# LM4F232H5QD register map
File version: 7944
Registers are 32-bit, read-write, no defined reset value unless marked. A register's access mark holds for its fields unless they carry their own. Offsets are from the block's base; [hi:lo] are bit positions; {n}, {i} and the like mark numbered series.

## SYSCTL — Register map for SYSCTL peripheral
Base 0x400FE000; register names take the prefix SYSCTL
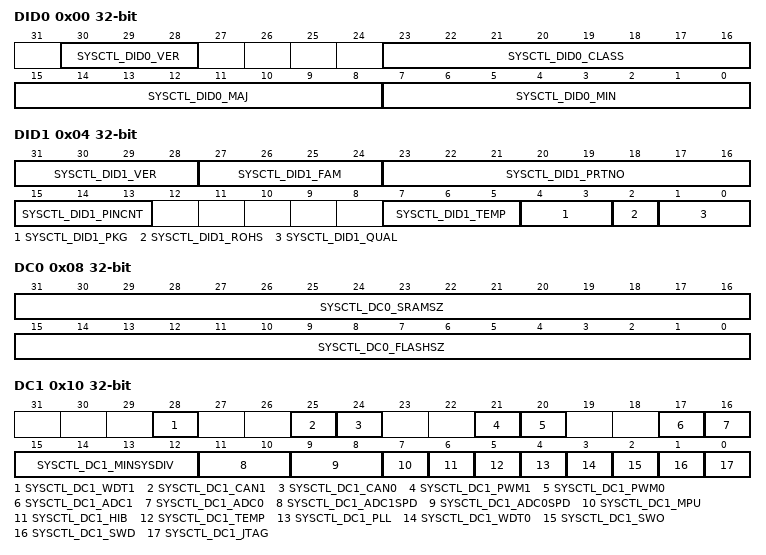
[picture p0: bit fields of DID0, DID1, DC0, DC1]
0x00 DID0 — Device Identification 0
  [30:28] SYSCTL_DID0_VER — DID0 Version
    1=Second version of the DID0 register format
  [23:16] SYSCTL_DID0_CLASS — Device Class
    5=SYSCTL_DID0_CLASS_BLIZZARD (Stellaris(R) Blizzard-class microcontrollers)
  [15:8] SYSCTL_DID0_MAJ — Major Revision
    0=SYSCTL_DID0_MAJ_REVA (Revision A (initial device)); 1=SYSCTL_DID0_MAJ_REVB (Revision B (first base layer revision)); 2=SYSCTL_DID0_MAJ_REVC (Revision C (second base layer revision))
  [7:0] SYSCTL_DID0_MIN — Minor Revision
    0=Initial device, or a major revision update; 1=First metal layer change; 2=Second metal layer change
0x04 DID1 — Device Identification 1
  [31:28] SYSCTL_DID1_VER — DID1 Version
    0=Initial DID1 register format definition, indicating a Stellaris LM3Snnn device; 1=Second version of the DID1 register format
  [27:24] SYSCTL_DID1_FAM — Family
    0=SYSCTL_DID1_FAM_STELLARIS (Stellaris family of microcontollers, that is, all devices with external part numbers starting with LM3S)
  [23:16] SYSCTL_DID1_PRTNO — Part Number
    197=SYSCTL_DID1_PRTNO_LM4F232H5QD (LM4F232H5QD)
  [15:13] SYSCTL_DID1_PINCNT — Package Pin Count
    0=28 pin package; 1=48-pin package; 2=100-pin package; 3=64-pin package; 4=144-pin package; 5=157-pin package
  [7:5] SYSCTL_DID1_TEMP — Temperature Range
    0=SYSCTL_DID1_TEMP_C (Commercial temperature range (0C to 70C)); 1=SYSCTL_DID1_TEMP_I (Industrial temperature range (-40C to 85C)); 2=SYSCTL_DID1_TEMP_E (Extended temperature range (-40C to 105C))
  [4:3] SYSCTL_DID1_PKG — Package Type
    0=SYSCTL_DID1_PKG_SOIC (SOIC package); 1=SYSCTL_DID1_PKG_QFP (LQFP package); 2=SYSCTL_DID1_PKG_BGA (BGA package)
  [2] SYSCTL_DID1_ROHS — RoHS-Compliance
  [1:0] SYSCTL_DID1_QUAL — Qualification Status
    0=SYSCTL_DID1_QUAL_ES (Engineering Sample (unqualified)); 1=SYSCTL_DID1_QUAL_PP (Pilot Production (unqualified)); 2=SYSCTL_DID1_QUAL_FQ (Fully Qualified)
0x08 DC0 — Device Capabilities 0
  [31:16] SYSCTL_DC0_SRAMSZ — SRAM Size
    7=SYSCTL_DC0_SRAMSZ_2KB (2 KB of SRAM); 15=SYSCTL_DC0_SRAMSZ_4KB (4 KB of SRAM); 23=SYSCTL_DC0_SRAMSZ_6KB (6 KB of SRAM); 31=SYSCTL_DC0_SRAMSZ_8KB (8 KB of SRAM); 47=SYSCTL_DC0_SRAMSZ_12KB (12 KB of SRAM); 63=SYSCTL_DC0_SRAMSZ_16KB (16 KB of SRAM); 79=SYSCTL_DC0_SRAMSZ_20KB (20 KB of SRAM); 95=SYSCTL_DC0_SRAMSZ_24KB (24 KB of SRAM); 127=SYSCTL_DC0_SRAMSZ_32KB (32 KB of SRAM)
  [15:0] SYSCTL_DC0_FLASHSZ — Flash Size
    3=SYSCTL_DC0_FLASHSZ_8KB (8 KB of Flash); 7=SYSCTL_DC0_FLASHSZ_16KB (16 KB of Flash); 15=SYSCTL_DC0_FLASHSZ_32KB (32 KB of Flash); 31=SYSCTL_DC0_FLASHSZ_64KB (64 KB of Flash); 47=SYSCTL_DC0_FLASHSZ_96KB (96 KB of Flash); 63=SYSCTL_DC0_FLASHSZ_128K (128 KB of Flash); 95=SYSCTL_DC0_FLASHSZ_192K (192 KB of Flash); 127=SYSCTL_DC0_FLASHSZ_256K (256 KB of Flash)
0x10 DC1 — Device Capabilities 1
  [28] SYSCTL_DC1_WDT1 — Watchdog Timer1 Present
  [25] SYSCTL_DC1_CAN1 — CAN Module 1 Present
  [24] SYSCTL_DC1_CAN0 — CAN Module 0 Present
  [21] SYSCTL_DC1_PWM1 — PWM Module 1 Present
  [20] SYSCTL_DC1_PWM0 — PWM Module 0 Present
  [17] SYSCTL_DC1_ADC1 — ADC Module 1 Present
  [16] SYSCTL_DC1_ADC0 — ADC Module 0 Present
  [15:12] SYSCTL_DC1_MINSYSDIV — System Clock Divider
    1=Divide VCO (400MHZ) by 5 minimum; 2=Divide VCO (400MHZ) by 2*2 + 2 = 6 minimum; 3=Specifies a 50-MHz CPU clock with a PLL divider of 4; 4=Specifies a 40-MHz CPU clock with a PLL divider of 5; 7=Specifies a 25-MHz clock with a PLL divider of 8; 9=Specifies a 20-MHz clock with a PLL divider of 10
  [11:10] SYSCTL_DC1_ADC1SPD — Max ADC1 Speed
    0=SYSCTL_DC1_ADC1SPD_125K (125K samples/second); 1=SYSCTL_DC1_ADC1SPD_250K (250K samples/second); 2=SYSCTL_DC1_ADC1SPD_500K (500K samples/second); 3=SYSCTL_DC1_ADC1SPD_1M (1M samples/second)
  [9:8] SYSCTL_DC1_ADC0SPD — Max ADC0 Speed
    0=SYSCTL_DC1_ADC0SPD_125K (125K samples/second); 1=SYSCTL_DC1_ADC0SPD_250K (250K samples/second); 2=SYSCTL_DC1_ADC0SPD_500K (500K samples/second); 3=SYSCTL_DC1_ADC0SPD_1M (1M samples/second)
  [7] SYSCTL_DC1_MPU — MPU Present
  [6] SYSCTL_DC1_HIB — Hibernation Module Present
  [5] SYSCTL_DC1_TEMP — Temp Sensor Present
  [4] SYSCTL_DC1_PLL — PLL Present
  [3] SYSCTL_DC1_WDT0 — Watchdog Timer 0 Present
  [2] SYSCTL_DC1_SWO — SWO Trace Port Present
  [1] SYSCTL_DC1_SWD — SWD Present
  [0] SYSCTL_DC1_JTAG — JTAG Present
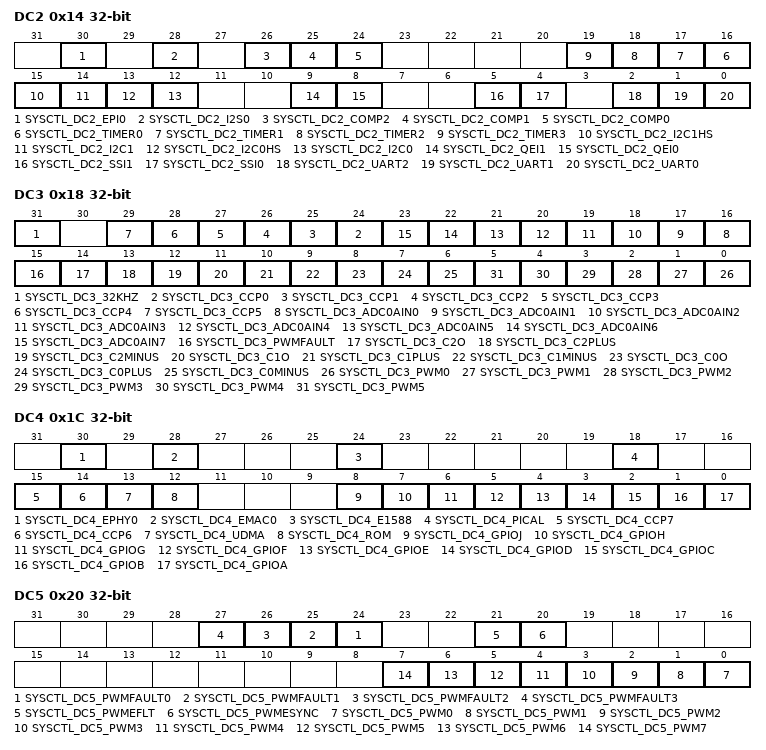
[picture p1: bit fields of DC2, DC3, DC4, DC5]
0x14 DC2 — Device Capabilities 2
  [30] SYSCTL_DC2_EPI0 — EPI Module 0 Present
  [28] SYSCTL_DC2_I2S0 — I2S Module 0 Present
  [26] SYSCTL_DC2_COMP2 — Analog Comparator 2 Present
  [25] SYSCTL_DC2_COMP1 — Analog Comparator 1 Present
  [24] SYSCTL_DC2_COMP0 — Analog Comparator 0 Present
  [n+16] SYSCTL_DC2_TIMER{n} (n=0..3) — Timer Module {n} Present
  [15] SYSCTL_DC2_I2C1HS — I2C Module 1 Speed
  [14] SYSCTL_DC2_I2C1 — I2C Module 1 Present
  [13] SYSCTL_DC2_I2C0HS — I2C Module 0 Speed
  [12] SYSCTL_DC2_I2C0 — I2C Module 0 Present
  [9] SYSCTL_DC2_QEI1 — QEI Module 1 Present
  [8] SYSCTL_DC2_QEI0 — QEI Module 0 Present
  [5] SYSCTL_DC2_SSI1 — SSI Module 1 Present
  [4] SYSCTL_DC2_SSI0 — SSI Module 0 Present
  [2] SYSCTL_DC2_UART2 — UART Module 2 Present
  [1] SYSCTL_DC2_UART1 — UART Module 1 Present
  [0] SYSCTL_DC2_UART0 — UART Module 0 Present
0x18 DC3 — Device Capabilities 3
  [31] SYSCTL_DC3_32KHZ — 32KHz Input Clock Available
  [n+24] SYSCTL_DC3_CCP{n} (n=0..5) — CCP{n} Pin Present
  [n+16] SYSCTL_DC3_ADC0AIN{n} (n=0..7) — ADC Module 0 AIN{n} Pin Present
  [15] SYSCTL_DC3_PWMFAULT — PWM Fault Pin Present
  [14] SYSCTL_DC3_C2O — C2o Pin Present
  [13] SYSCTL_DC3_C2PLUS — C2+ Pin Present
  [12] SYSCTL_DC3_C2MINUS — C2- Pin Present
  [11] SYSCTL_DC3_C1O — C1o Pin Present
  [10] SYSCTL_DC3_C1PLUS — C1+ Pin Present
  [9] SYSCTL_DC3_C1MINUS — C1- Pin Present
  [8] SYSCTL_DC3_C0O — C0o Pin Present
  [7] SYSCTL_DC3_C0PLUS — C0+ Pin Present
  [6] SYSCTL_DC3_C0MINUS — C0- Pin Present
  [n] SYSCTL_DC3_PWM{n} (n=0..5) — PWM{n} Pin Present
0x1C DC4 — Device Capabilities 4
  [30] SYSCTL_DC4_EPHY0 — Ethernet PHY Layer 0 Present
  [28] SYSCTL_DC4_EMAC0 — Ethernet MAC Layer 0 Present
  [24] SYSCTL_DC4_E1588 — 1588 Capable
  [18] SYSCTL_DC4_PICAL — PIOSC Calibrate
  [15] SYSCTL_DC4_CCP7 — CCP7 Pin Present
  [14] SYSCTL_DC4_CCP6 — CCP6 Pin Present
  [13] SYSCTL_DC4_UDMA — Micro-DMA Module Present
  [12] SYSCTL_DC4_ROM — Internal Code ROM Present
  [8] SYSCTL_DC4_GPIOJ — GPIO Port J Present
  [7] SYSCTL_DC4_GPIOH — GPIO Port H Present
  [6] SYSCTL_DC4_GPIOG — GPIO Port G Present
  [5] SYSCTL_DC4_GPIOF — GPIO Port F Present
  [4] SYSCTL_DC4_GPIOE — GPIO Port E Present
  [3] SYSCTL_DC4_GPIOD — GPIO Port D Present
  [2] SYSCTL_DC4_GPIOC — GPIO Port C Present
  [1] SYSCTL_DC4_GPIOB — GPIO Port B Present
  [0] SYSCTL_DC4_GPIOA — GPIO Port A Present
0x20 DC5 — Device Capabilities 5
  [n+24] SYSCTL_DC5_PWMFAULT{n} (n=0..3) — PWM Fault {n} Pin Present
  [21] SYSCTL_DC5_PWMEFLT — PWM Extended Fault Active
  [20] SYSCTL_DC5_PWMESYNC — PWM Extended SYNC Active
  [n] SYSCTL_DC5_PWM{n} (n=0..7) — PWM{n} Pin Present
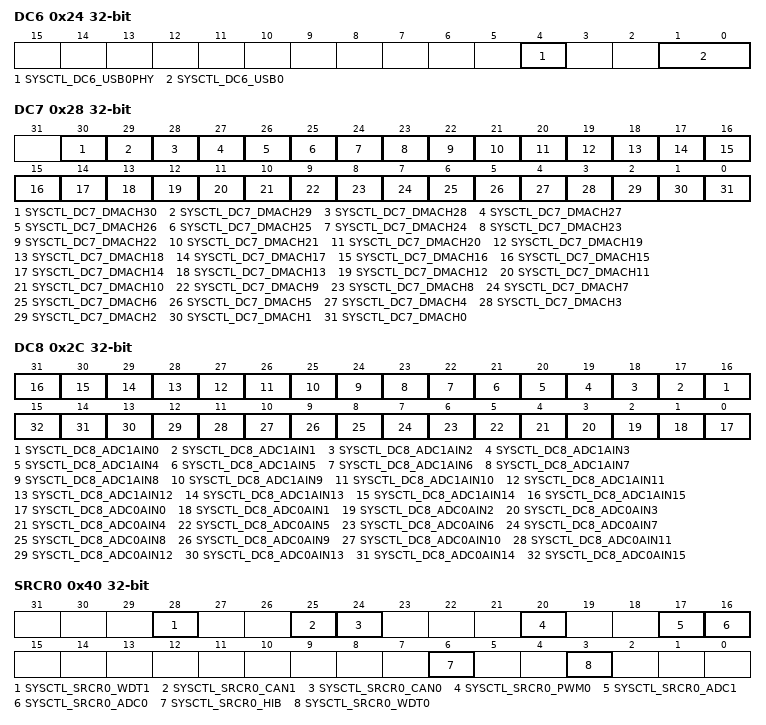
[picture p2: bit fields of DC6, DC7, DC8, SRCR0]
0x24 DC6 — Device Capabilities 6
  [4] SYSCTL_DC6_USB0PHY — USB Module 0 PHY Present
  [1:0] SYSCTL_DC6_USB0 — USB Module 0 Present
    1=SYSCTL_DC6_USB0_DEV (USB0 is Device Only); 2=SYSCTL_DC6_USB0_HOSTDEV (USB is Device or Host); 3=SYSCTL_DC6_USB0_OTG (USB0 is OTG)
0x28 DC7 — Device Capabilities 7
  [30] SYSCTL_DC7_DMACH30 — SW
  [29] SYSCTL_DC7_DMACH29 — I2S0_TX / CAN1_TX
  [28] SYSCTL_DC7_DMACH28 — I2S0_RX / CAN1_RX
  [27] SYSCTL_DC7_DMACH27 — CAN1_TX / ADC1_SS3
  [26] SYSCTL_DC7_DMACH26 — CAN1_RX / ADC1_SS2
  [25] SYSCTL_DC7_DMACH25 — SSI1_TX / ADC1_SS1
  [24] SYSCTL_DC7_DMACH24 — SSI1_RX / ADC1_SS0
  [23] SYSCTL_DC7_DMACH23 — UART1_TX / CAN2_TX
  [22] SYSCTL_DC7_DMACH22 — UART1_RX / CAN2_RX
  [21] SYSCTL_DC7_DMACH21 — Timer1B / EPI0_WFIFO
  [20] SYSCTL_DC7_DMACH20 — Timer1A / EPI0_NBRFIFO
  [19] SYSCTL_DC7_DMACH19 — Timer0B / Timer1B
  [18] SYSCTL_DC7_DMACH18 — Timer0A / Timer1A
  [17] SYSCTL_DC7_DMACH17 — ADC0_SS3
  [16] SYSCTL_DC7_DMACH16 — ADC0_SS2
  [15] SYSCTL_DC7_DMACH15 — ADC0_SS1 / Timer2B
  [14] SYSCTL_DC7_DMACH14 — ADC0_SS0 / Timer2A
  [13] SYSCTL_DC7_DMACH13 — CAN0_TX / UART2_TX
  [12] SYSCTL_DC7_DMACH12 — CAN0_RX / UART2_RX
  [11] SYSCTL_DC7_DMACH11 — SSI0_TX / SSI1_TX
  [10] SYSCTL_DC7_DMACH10 — SSI0_RX / SSI1_RX
  [9] SYSCTL_DC7_DMACH9 — UART0_TX / UART1_TX
  [8] SYSCTL_DC7_DMACH8 — UART0_RX / UART1_RX
  [7] SYSCTL_DC7_DMACH7 — ETH_TX / Timer2B
  [6] SYSCTL_DC7_DMACH6 — ETH_RX / Timer2A
  [5] SYSCTL_DC7_DMACH5 — USB_EP3_TX / Timer2B
  [4] SYSCTL_DC7_DMACH4 — USB_EP3_RX / Timer2A
  [3] SYSCTL_DC7_DMACH3 — USB_EP2_TX / Timer3B
  [2] SYSCTL_DC7_DMACH2 — USB_EP2_RX / Timer3A
  [1] SYSCTL_DC7_DMACH1 — USB_EP1_TX / UART2_TX
  [0] SYSCTL_DC7_DMACH0 — USB_EP1_RX / UART2_RX
0x2C DC8 — Device Capabilities 8 ADC Channels
  [n+16] SYSCTL_DC8_ADC1AIN{n} (n=0..15) — ADC Module 1 AIN{n} Pin Present
  [n] SYSCTL_DC8_ADC0AIN{n} (n=0..15) — ADC Module 0 AIN{n} Pin Present
0x30 PBORCTL — Brown-Out Reset Control
  [1] SYSCTL_PBORCTL_BORIOR — BOR Interrupt or Reset
0x40 SRCR0 — Software Reset Control 0
  [28] SYSCTL_SRCR0_WDT1 — WDT1 Reset Control
  [25] SYSCTL_SRCR0_CAN1 — CAN1 Reset Control
  [24] SYSCTL_SRCR0_CAN0 — CAN0 Reset Control
  [20] SYSCTL_SRCR0_PWM0 — PWM Reset Control
  [17] SYSCTL_SRCR0_ADC1 — ADC1 Reset Control
  [16] SYSCTL_SRCR0_ADC0 — ADC0 Reset Control
  [6] SYSCTL_SRCR0_HIB — HIB Reset Control
  [3] SYSCTL_SRCR0_WDT0 — WDT0 Reset Control
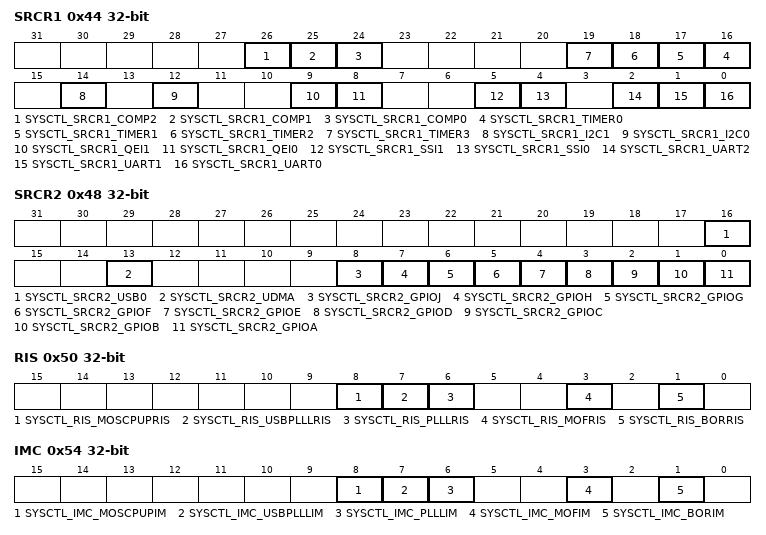
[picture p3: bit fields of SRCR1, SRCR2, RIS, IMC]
0x44 SRCR1 — Software Reset Control 1
  [26] SYSCTL_SRCR1_COMP2 — Analog Comp 2 Reset Control
  [25] SYSCTL_SRCR1_COMP1 — Analog Comp 1 Reset Control
  [24] SYSCTL_SRCR1_COMP0 — Analog Comp 0 Reset Control
  [n+16] SYSCTL_SRCR1_TIMER{n} (n=0..3) — Timer {n} Reset Control
  [14] SYSCTL_SRCR1_I2C1 — I2C1 Reset Control
  [12] SYSCTL_SRCR1_I2C0 — I2C0 Reset Control
  [9] SYSCTL_SRCR1_QEI1 — QEI1 Reset Control
  [8] SYSCTL_SRCR1_QEI0 — QEI0 Reset Control
  [5] SYSCTL_SRCR1_SSI1 — SSI1 Reset Control
  [4] SYSCTL_SRCR1_SSI0 — SSI0 Reset Control
  [2] SYSCTL_SRCR1_UART2 — UART2 Reset Control
  [1] SYSCTL_SRCR1_UART1 — UART1 Reset Control
  [0] SYSCTL_SRCR1_UART0 — UART0 Reset Control
0x48 SRCR2 — Software Reset Control 2
  [16] SYSCTL_SRCR2_USB0 — USB0 Reset Control
  [13] SYSCTL_SRCR2_UDMA — Micro-DMA Reset Control
  [8] SYSCTL_SRCR2_GPIOJ — Port J Reset Control
  [7] SYSCTL_SRCR2_GPIOH — Port H Reset Control
  [6] SYSCTL_SRCR2_GPIOG — Port G Reset Control
  [5] SYSCTL_SRCR2_GPIOF — Port F Reset Control
  [4] SYSCTL_SRCR2_GPIOE — Port E Reset Control
  [3] SYSCTL_SRCR2_GPIOD — Port D Reset Control
  [2] SYSCTL_SRCR2_GPIOC — Port C Reset Control
  [1] SYSCTL_SRCR2_GPIOB — Port B Reset Control
  [0] SYSCTL_SRCR2_GPIOA — Port A Reset Control
0x50 RIS — Raw Interrupt Status
  [8] SYSCTL_RIS_MOSCPUPRIS — MOSC Power Up Raw Interrupt Status
  [7] SYSCTL_RIS_USBPLLLRIS — USB PLL Lock Raw Interrupt Status
  [6] SYSCTL_RIS_PLLLRIS — PLL Lock Raw Interrupt Status
  [3] SYSCTL_RIS_MOFRIS — Main Oscillator Fault Raw Interrupt Status
  [1] SYSCTL_RIS_BORRIS — Brown-Out Reset Raw Interrupt Status
0x54 IMC — Interrupt Mask Control
  [8] SYSCTL_IMC_MOSCPUPIM — MOSC Power Up Interrupt Mask
  [7] SYSCTL_IMC_USBPLLLIM — USB PLL Lock Interrupt Mask
  [6] SYSCTL_IMC_PLLLIM — PLL Lock Interrupt Mask
  [3] SYSCTL_IMC_MOFIM — Main Oscillator Fault Interrupt Mask
  [1] SYSCTL_IMC_BORIM — Brown-Out Reset Interrupt Mask
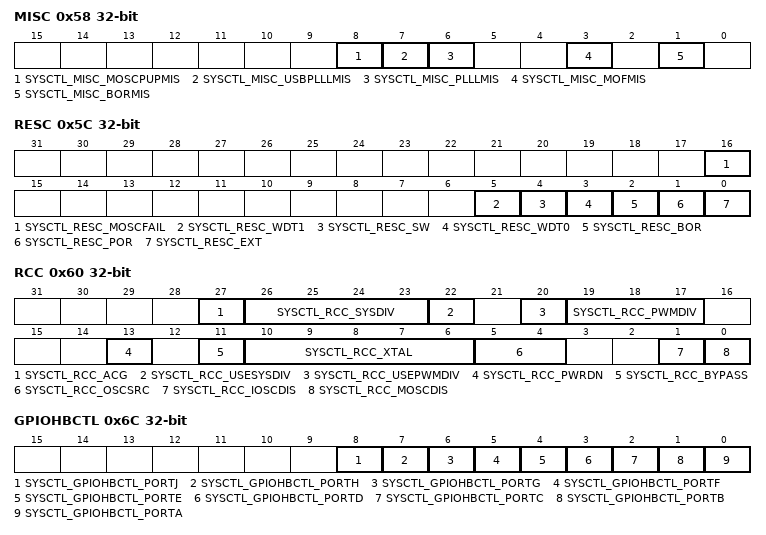
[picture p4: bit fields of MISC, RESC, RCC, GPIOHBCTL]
0x58 MISC — Masked Interrupt Status and Clear
  [8] SYSCTL_MISC_MOSCPUPMIS — MOSC Power Up Masked Interrupt Status
  [7] SYSCTL_MISC_USBPLLLMIS — USB PLL Lock Masked Interrupt Status
  [6] SYSCTL_MISC_PLLLMIS — PLL Lock Masked Interrupt Status
  [3] SYSCTL_MISC_MOFMIS — Main Oscillator Fault Masked Interrupt Status
  [1] SYSCTL_MISC_BORMIS — BOR Masked Interrupt Status
0x5C RESC — Reset Cause
  [16] SYSCTL_RESC_MOSCFAIL — MOSC Failure Reset
  [5] SYSCTL_RESC_WDT1 — Watchdog Timer 1 Reset
  [4] SYSCTL_RESC_SW — Software Reset
  [3] SYSCTL_RESC_WDT0 — Watchdog Timer 0 Reset
  [2] SYSCTL_RESC_BOR — Brown-Out Reset
  [1] SYSCTL_RESC_POR — Power-On Reset
  [0] SYSCTL_RESC_EXT — External Reset
0x60 RCC — Run-Mode Clock Configuration
  [27] SYSCTL_RCC_ACG — Auto Clock Gating
  [26:23] SYSCTL_RCC_SYSDIV — System Clock Divisor
  [22] SYSCTL_RCC_USESYSDIV — Enable System Clock Divider
  [20] SYSCTL_RCC_USEPWMDIV — Enable PWM Clock Divisor
  [19:17] SYSCTL_RCC_PWMDIV — PWM Unit Clock Divisor
    0=PWM clock /2; 1=PWM clock /4; 2=PWM clock /8; 3=PWM clock /16; 4=PWM clock /32; 5=PWM clock /64
  [13] SYSCTL_RCC_PWRDN — PLL Power Down
  [11] SYSCTL_RCC_BYPASS — PLL Bypass
  [10:6] SYSCTL_RCC_XTAL — Crystal Value
    6=SYSCTL_RCC_XTAL_4MHZ (4 MHz); 7=SYSCTL_RCC_XTAL_4_09MHZ (4.096 MHz); 8=SYSCTL_RCC_XTAL_4_91MHZ (4.9152 MHz); 9=SYSCTL_RCC_XTAL_5MHZ (5 MHz); 10=SYSCTL_RCC_XTAL_5_12MHZ (5.12 MHz); 11=SYSCTL_RCC_XTAL_6MHZ (6 MHz); 12=SYSCTL_RCC_XTAL_6_14MHZ (6.144 MHz); 13=SYSCTL_RCC_XTAL_7_37MHZ (7.3728 MHz); 14=SYSCTL_RCC_XTAL_8MHZ (8 MHz); 15=SYSCTL_RCC_XTAL_8_19MHZ (8.192 MHz); 16=SYSCTL_RCC_XTAL_10MHZ (10 MHz); 17=SYSCTL_RCC_XTAL_12MHZ (12 MHz); 18=SYSCTL_RCC_XTAL_12_2MHZ (12.288 MHz); 19=SYSCTL_RCC_XTAL_13_5MHZ (13.56 MHz); 20=SYSCTL_RCC_XTAL_14_3MHZ (14.31818 MHz); 21=SYSCTL_RCC_XTAL_16MHZ (16 MHz); 22=SYSCTL_RCC_XTAL_16_3MHZ (16.384 MHz); 23=SYSCTL_RCC_XTAL_18MHZ (18.0 MHz); 24=SYSCTL_RCC_XTAL_20MHZ (20.0 MHz); 25=SYSCTL_RCC_XTAL_24MHZ (24.0 MHz); 26=SYSCTL_RCC_XTAL_25MHZ (25.0 MHz)
  [5:4] SYSCTL_RCC_OSCSRC — Oscillator Source
    0=SYSCTL_RCC_OSCSRC_MAIN (MOSC); 1=SYSCTL_RCC_OSCSRC_INT (IOSC); 2=SYSCTL_RCC_OSCSRC_INT4 (IOSC/4); 3=30 kHz
  [1] SYSCTL_RCC_IOSCDIS — Internal Oscillator Disable
  [0] SYSCTL_RCC_MOSCDIS — Main Oscillator Disable
0x6C GPIOHBCTL — GPIO High-Performance Bus Control
  [8] SYSCTL_GPIOHBCTL_PORTJ — Port J Advanced High-Performance Bus
  [7] SYSCTL_GPIOHBCTL_PORTH — Port H Advanced High-Performance Bus
  [6] SYSCTL_GPIOHBCTL_PORTG — Port G Advanced High-Performance Bus
  [5] SYSCTL_GPIOHBCTL_PORTF — Port F Advanced High-Performance Bus
  [4] SYSCTL_GPIOHBCTL_PORTE — Port E Advanced High-Performance Bus
  [3] SYSCTL_GPIOHBCTL_PORTD — Port D Advanced High-Performance Bus
  [2] SYSCTL_GPIOHBCTL_PORTC — Port C Advanced High-Performance Bus
  [1] SYSCTL_GPIOHBCTL_PORTB — Port B Advanced High-Performance Bus
  [0] SYSCTL_GPIOHBCTL_PORTA — Port A Advanced High-Performance Bus
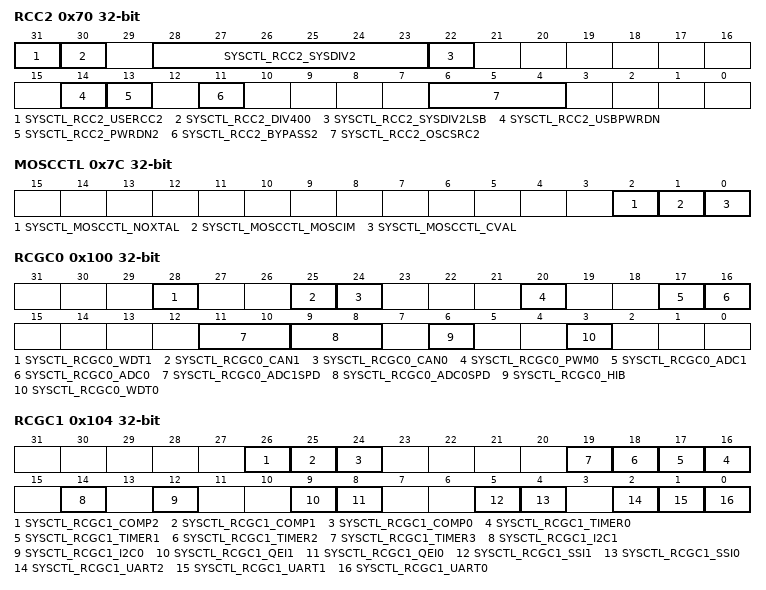
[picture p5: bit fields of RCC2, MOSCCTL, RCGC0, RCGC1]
0x70 RCC2 — Run-Mode Clock Configuration 2
  [31] SYSCTL_RCC2_USERCC2 — Use RCC2
  [30] SYSCTL_RCC2_DIV400 — Divide PLL as 400 MHz vs. 200 MHz
  [28:23] SYSCTL_RCC2_SYSDIV2 — System Clock Divisor 2
    {v}=System clock /{v+1} (v=1..63)
  [22] SYSCTL_RCC2_SYSDIV2LSB — Additional LSB for SYSDIV2
  [14] SYSCTL_RCC2_USBPWRDN — Power-Down USB PLL
  [13] SYSCTL_RCC2_PWRDN2 — Power-Down PLL 2
  [11] SYSCTL_RCC2_BYPASS2 — PLL Bypass 2
  [6:4] SYSCTL_RCC2_OSCSRC2 — Oscillator Source 2
    0=SYSCTL_RCC2_OSCSRC2_MO (MOSC); 1=SYSCTL_RCC2_OSCSRC2_IO (PIOSC); 2=SYSCTL_RCC2_OSCSRC2_IO4 (PIOSC/4); 3=30 kHz; 7=32.768 kHz
0x7C MOSCCTL — Main Oscillator Control
  [2] SYSCTL_MOSCCTL_NOXTAL — No Crystal Connected
  [1] SYSCTL_MOSCCTL_MOSCIM — MOSC Failure Action
  [0] SYSCTL_MOSCCTL_CVAL — Clock Validation for MOSC
0x100 RCGC0 — Run Mode Clock Gating Control Register 0
  [28] SYSCTL_RCGC0_WDT1 — WDT1 Clock Gating Control
  [25] SYSCTL_RCGC0_CAN1 — CAN1 Clock Gating Control
  [24] SYSCTL_RCGC0_CAN0 — CAN0 Clock Gating Control
  [20] SYSCTL_RCGC0_PWM0 — PWM Clock Gating Control
  [17] SYSCTL_RCGC0_ADC1 — ADC1 Clock Gating Control
  [16] SYSCTL_RCGC0_ADC0 — ADC0 Clock Gating Control
  [11:10] SYSCTL_RCGC0_ADC1SPD — ADC1 Sample Speed
    0=SYSCTL_RCGC0_ADC1SPD_125K (125K samples/second); 1=SYSCTL_RCGC0_ADC1SPD_250K (250K samples/second); 2=SYSCTL_RCGC0_ADC1SPD_500K (500K samples/second); 3=SYSCTL_RCGC0_ADC1SPD_1M (1M samples/second)
  [9:8] SYSCTL_RCGC0_ADC0SPD — ADC0 Sample Speed
    0=SYSCTL_RCGC0_ADC0SPD_125K (125K samples/second); 1=SYSCTL_RCGC0_ADC0SPD_250K (250K samples/second); 2=SYSCTL_RCGC0_ADC0SPD_500K (500K samples/second); 3=SYSCTL_RCGC0_ADC0SPD_1M (1M samples/second)
  [6] SYSCTL_RCGC0_HIB — HIB Clock Gating Control
  [3] SYSCTL_RCGC0_WDT0 — WDT0 Clock Gating Control
0x104 RCGC1 — Run Mode Clock Gating Control Register 1
  [26] SYSCTL_RCGC1_COMP2 — Analog Comparator 2 Clock Gating
  [25] SYSCTL_RCGC1_COMP1 — Analog Comparator 1 Clock Gating
  [24] SYSCTL_RCGC1_COMP0 — Analog Comparator 0 Clock Gating
  [n+16] SYSCTL_RCGC1_TIMER{n} (n=0..3) — Timer {n} Clock Gating Control
  [14] SYSCTL_RCGC1_I2C1 — I2C1 Clock Gating Control
  [12] SYSCTL_RCGC1_I2C0 — I2C0 Clock Gating Control
  [9] SYSCTL_RCGC1_QEI1 — QEI1 Clock Gating Control
  [8] SYSCTL_RCGC1_QEI0 — QEI0 Clock Gating Control
  [5] SYSCTL_RCGC1_SSI1 — SSI1 Clock Gating Control
  [4] SYSCTL_RCGC1_SSI0 — SSI0 Clock Gating Control
  [2] SYSCTL_RCGC1_UART2 — UART2 Clock Gating Control
  [1] SYSCTL_RCGC1_UART1 — UART1 Clock Gating Control
  [0] SYSCTL_RCGC1_UART0 — UART0 Clock Gating Control
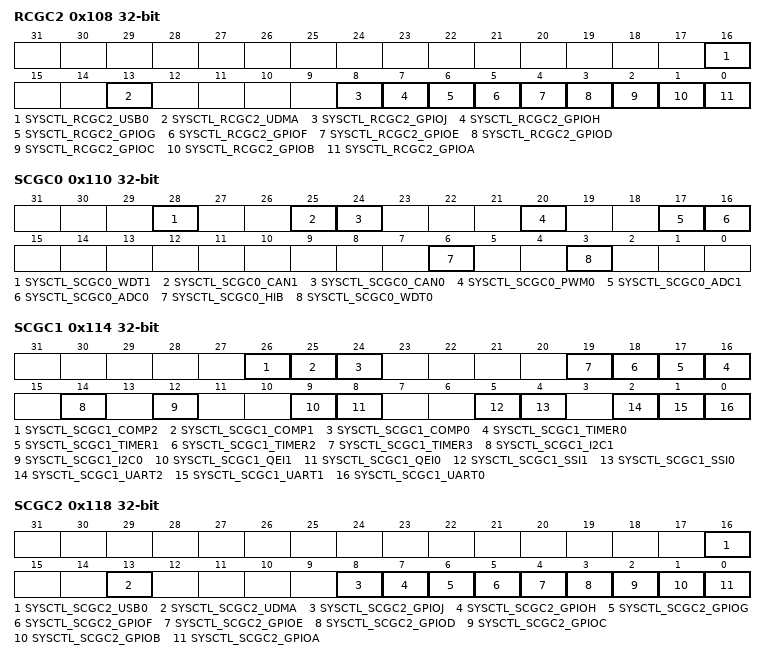
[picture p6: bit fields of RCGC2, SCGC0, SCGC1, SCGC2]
0x108 RCGC2 — Run Mode Clock Gating Control Register 2
  [16] SYSCTL_RCGC2_USB0 — USB0 Clock Gating Control
  [13] SYSCTL_RCGC2_UDMA — Micro-DMA Clock Gating Control
  [8] SYSCTL_RCGC2_GPIOJ — Port J Clock Gating Control
  [7] SYSCTL_RCGC2_GPIOH — Port H Clock Gating Control
  [6] SYSCTL_RCGC2_GPIOG — Port G Clock Gating Control
  [5] SYSCTL_RCGC2_GPIOF — Port F Clock Gating Control
  [4] SYSCTL_RCGC2_GPIOE — Port E Clock Gating Control
  [3] SYSCTL_RCGC2_GPIOD — Port D Clock Gating Control
  [2] SYSCTL_RCGC2_GPIOC — Port C Clock Gating Control
  [1] SYSCTL_RCGC2_GPIOB — Port B Clock Gating Control
  [0] SYSCTL_RCGC2_GPIOA — Port A Clock Gating Control
0x110 SCGC0 — Sleep Mode Clock Gating Control Register 0
  [28] SYSCTL_SCGC0_WDT1 — WDT1 Clock Gating Control
  [25] SYSCTL_SCGC0_CAN1 — CAN1 Clock Gating Control
  [24] SYSCTL_SCGC0_CAN0 — CAN0 Clock Gating Control
  [20] SYSCTL_SCGC0_PWM0 — PWM Clock Gating Control
  [17] SYSCTL_SCGC0_ADC1 — ADC1 Clock Gating Control
  [16] SYSCTL_SCGC0_ADC0 — ADC0 Clock Gating Control
  [6] SYSCTL_SCGC0_HIB — HIB Clock Gating Control
  [3] SYSCTL_SCGC0_WDT0 — WDT0 Clock Gating Control
0x114 SCGC1 — Sleep Mode Clock Gating Control Register 1
  [26] SYSCTL_SCGC1_COMP2 — Analog Comparator 2 Clock Gating
  [25] SYSCTL_SCGC1_COMP1 — Analog Comparator 1 Clock Gating
  [24] SYSCTL_SCGC1_COMP0 — Analog Comparator 0 Clock Gating
  [n+16] SYSCTL_SCGC1_TIMER{n} (n=0..3) — Timer {n} Clock Gating Control
  [14] SYSCTL_SCGC1_I2C1 — I2C1 Clock Gating Control
  [12] SYSCTL_SCGC1_I2C0 — I2C0 Clock Gating Control
  [9] SYSCTL_SCGC1_QEI1 — QEI1 Clock Gating Control
  [8] SYSCTL_SCGC1_QEI0 — QEI0 Clock Gating Control
  [5] SYSCTL_SCGC1_SSI1 — SSI1 Clock Gating Control
  [4] SYSCTL_SCGC1_SSI0 — SSI0 Clock Gating Control
  [2] SYSCTL_SCGC1_UART2 — UART2 Clock Gating Control
  [1] SYSCTL_SCGC1_UART1 — UART1 Clock Gating Control
  [0] SYSCTL_SCGC1_UART0 — UART0 Clock Gating Control
0x118 SCGC2 — Sleep Mode Clock Gating Control Register 2
  [16] SYSCTL_SCGC2_USB0 — USB0 Clock Gating Control
  [13] SYSCTL_SCGC2_UDMA — Micro-DMA Clock Gating Control
  [8] SYSCTL_SCGC2_GPIOJ — Port J Clock Gating Control
  [7] SYSCTL_SCGC2_GPIOH — Port H Clock Gating Control
  [6] SYSCTL_SCGC2_GPIOG — Port G Clock Gating Control
  [5] SYSCTL_SCGC2_GPIOF — Port F Clock Gating Control
  [4] SYSCTL_SCGC2_GPIOE — Port E Clock Gating Control
  [3] SYSCTL_SCGC2_GPIOD — Port D Clock Gating Control
  [2] SYSCTL_SCGC2_GPIOC — Port C Clock Gating Control
  [1] SYSCTL_SCGC2_GPIOB — Port B Clock Gating Control
  [0] SYSCTL_SCGC2_GPIOA — Port A Clock Gating Control
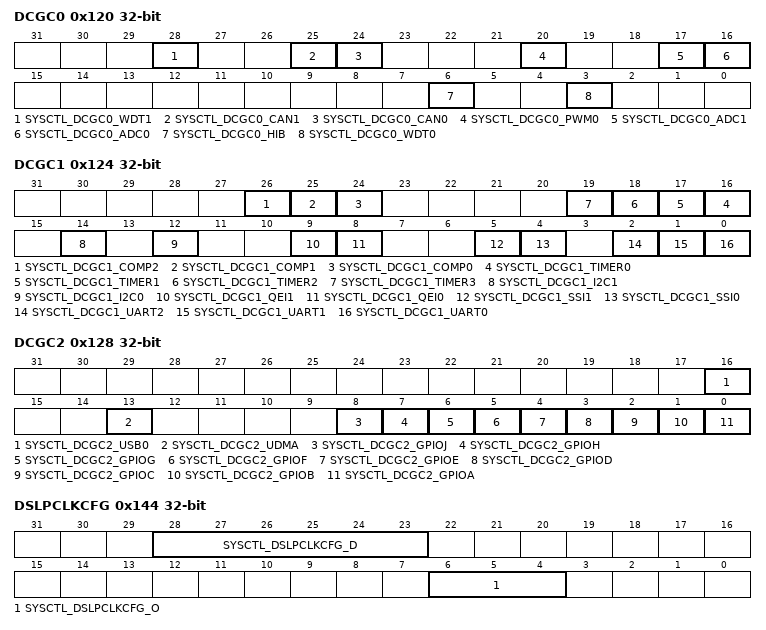
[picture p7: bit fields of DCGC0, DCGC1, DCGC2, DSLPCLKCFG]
0x120 DCGC0 — Deep Sleep Mode Clock Gating Control Register 0
  [28] SYSCTL_DCGC0_WDT1 — WDT1 Clock Gating Control
  [25] SYSCTL_DCGC0_CAN1 — CAN1 Clock Gating Control
  [24] SYSCTL_DCGC0_CAN0 — CAN0 Clock Gating Control
  [20] SYSCTL_DCGC0_PWM0 — PWM Clock Gating Control
  [17] SYSCTL_DCGC0_ADC1 — ADC1 Clock Gating Control
  [16] SYSCTL_DCGC0_ADC0 — ADC0 Clock Gating Control
  [6] SYSCTL_DCGC0_HIB — HIB Clock Gating Control
  [3] SYSCTL_DCGC0_WDT0 — WDT0 Clock Gating Control
0x124 DCGC1 — Deep-Sleep Mode Clock Gating Control Register 1
  [26] SYSCTL_DCGC1_COMP2 — Analog Comparator 2 Clock Gating
  [25] SYSCTL_DCGC1_COMP1 — Analog Comparator 1 Clock Gating
  [24] SYSCTL_DCGC1_COMP0 — Analog Comparator 0 Clock Gating
  [n+16] SYSCTL_DCGC1_TIMER{n} (n=0..3) — Timer {n} Clock Gating Control
  [14] SYSCTL_DCGC1_I2C1 — I2C1 Clock Gating Control
  [12] SYSCTL_DCGC1_I2C0 — I2C0 Clock Gating Control
  [9] SYSCTL_DCGC1_QEI1 — QEI1 Clock Gating Control
  [8] SYSCTL_DCGC1_QEI0 — QEI0 Clock Gating Control
  [5] SYSCTL_DCGC1_SSI1 — SSI1 Clock Gating Control
  [4] SYSCTL_DCGC1_SSI0 — SSI0 Clock Gating Control
  [2] SYSCTL_DCGC1_UART2 — UART2 Clock Gating Control
  [1] SYSCTL_DCGC1_UART1 — UART1 Clock Gating Control
  [0] SYSCTL_DCGC1_UART0 — UART0 Clock Gating Control
0x128 DCGC2 — Deep Sleep Mode Clock Gating Control Register 2
  [16] SYSCTL_DCGC2_USB0 — USB0 Clock Gating Control
  [13] SYSCTL_DCGC2_UDMA — Micro-DMA Clock Gating Control
  [8] SYSCTL_DCGC2_GPIOJ — Port J Clock Gating Control
  [7] SYSCTL_DCGC2_GPIOH — Port H Clock Gating Control
  [6] SYSCTL_DCGC2_GPIOG — Port G Clock Gating Control
  [5] SYSCTL_DCGC2_GPIOF — Port F Clock Gating Control
  [4] SYSCTL_DCGC2_GPIOE — Port E Clock Gating Control
  [3] SYSCTL_DCGC2_GPIOD — Port D Clock Gating Control
  [2] SYSCTL_DCGC2_GPIOC — Port C Clock Gating Control
  [1] SYSCTL_DCGC2_GPIOB — Port B Clock Gating Control
  [0] SYSCTL_DCGC2_GPIOA — Port A Clock Gating Control
0x144 DSLPCLKCFG — Deep Sleep Clock Configuration
  [28:23] SYSCTL_DSLPCLKCFG_D — Divider Field Override
    {v}=System clock /{v+1} (v=0..3); 63=System clock /64
  [6:4] SYSCTL_DSLPCLKCFG_O — Clock Source
    0=SYSCTL_DSLPCLKCFG_O_IGN (MOSC); 1=SYSCTL_DSLPCLKCFG_O_IO (PIOSC); 3=30 kHz; 7=32.768 kHz
0x14C SYSPROP — System Properties
  [0] SYSCTL_SYSPROP_FPU — FPU Present
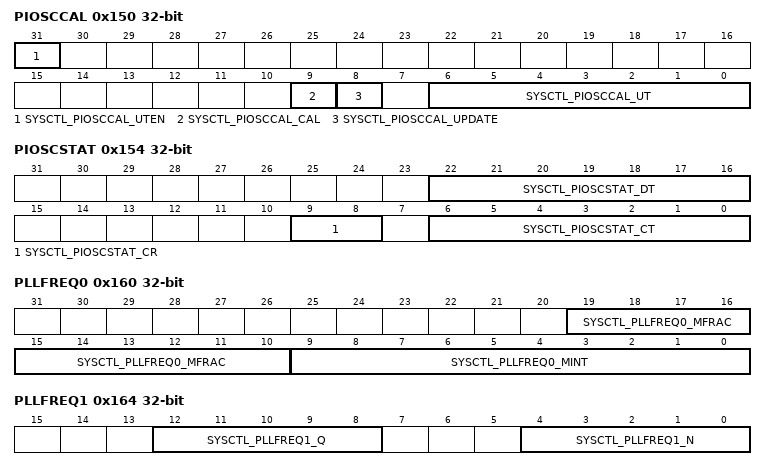
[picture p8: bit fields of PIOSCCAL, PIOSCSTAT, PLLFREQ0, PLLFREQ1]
0x150 PIOSCCAL — Precision Internal Oscillator Calibration
  [31] SYSCTL_PIOSCCAL_UTEN — Use User Trim Value
  [9] SYSCTL_PIOSCCAL_CAL — Start Calibration
  [8] SYSCTL_PIOSCCAL_UPDATE — Update Trim
  [6:0] SYSCTL_PIOSCCAL_UT — User Trim Value
0x154 PIOSCSTAT — Precision Internal Oscillator Statistics
  [22:16] SYSCTL_PIOSCSTAT_DT — Default Trim Value
  [9:8] SYSCTL_PIOSCSTAT_CR — Calibration Result
    0=SYSCTL_PIOSCSTAT_CRNONE (Calibration has not been attempted); 1=SYSCTL_PIOSCSTAT_CRPASS (The last calibration operation completed to meet 1% accuracy); 2=SYSCTL_PIOSCSTAT_CRFAIL (The last calibration operation failed to meet 1% accuracy)
  [6:0] SYSCTL_PIOSCSTAT_CT — Calibration Trim Value
0x160 PLLFREQ0 — PLL Frequency 0
  [19:10] SYSCTL_PLLFREQ0_MFRAC — PLL M Fractional Value
  [9:0] SYSCTL_PLLFREQ0_MINT — PLL M Integer Value
0x164 PLLFREQ1 — PLL Frequency
  [12:8] SYSCTL_PLLFREQ1_Q — PLL Q Value
  [4:0] SYSCTL_PLLFREQ1_N — PLL N Value
0x168 PLLSTAT — PLL Status
  [0] SYSCTL_PLLSTAT_LOCK — PLL Lock
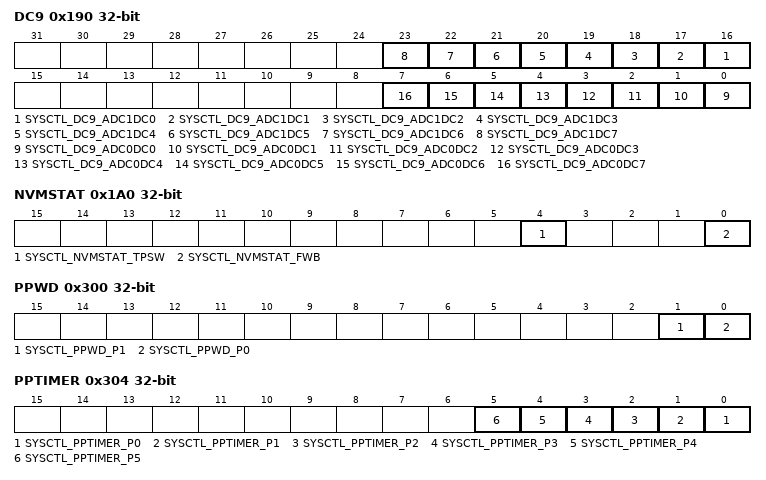
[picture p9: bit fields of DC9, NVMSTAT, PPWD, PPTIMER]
0x190 DC9 — Device Capabilities 9 ADC Digital Comparators
  [n+16] SYSCTL_DC9_ADC1DC{n} (n=0..7) — ADC1 DC{n} Present
  [n] SYSCTL_DC9_ADC0DC{n} (n=0..7) — ADC0 DC{n} Present
0x1A0 NVMSTAT — Non-Volatile Memory Information
  [4] SYSCTL_NVMSTAT_TPSW — Third Party Software Present
  [0] SYSCTL_NVMSTAT_FWB — 32 Word Flash Write Buffer Active
0x300 PPWD — Watchdog Timer Peripheral Present
  [1] SYSCTL_PPWD_P1 — Watchdog Timer 1 Present
  [0] SYSCTL_PPWD_P0 — Watchdog Timer 0 Present
0x304 PPTIMER — Timer Peripheral Present
  [n] SYSCTL_PPTIMER_P{n} (n=0..5) — Timer {n} Present
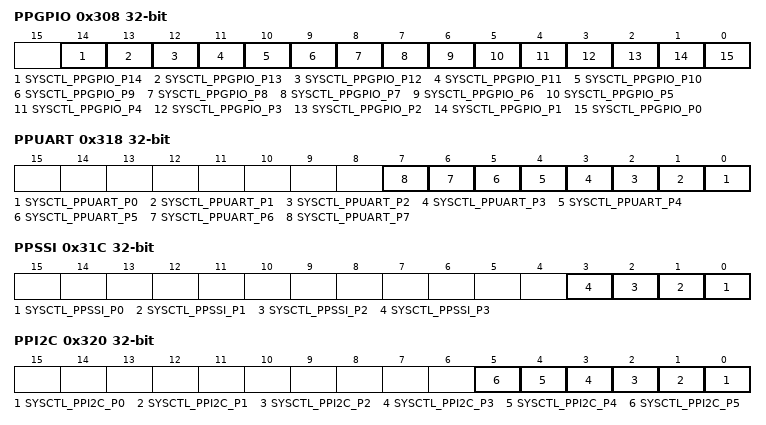
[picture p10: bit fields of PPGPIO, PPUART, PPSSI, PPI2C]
0x308 PPGPIO — General-Purpose Input/Output Peripheral Present
  [14] SYSCTL_PPGPIO_P14 — GPIO Port Q Present
  [13] SYSCTL_PPGPIO_P13 — GPIO Port P Present
  [12] SYSCTL_PPGPIO_P12 — GPIO Port N Present
  [11] SYSCTL_PPGPIO_P11 — GPIO Port M Present
  [10] SYSCTL_PPGPIO_P10 — GPIO Port L Present
  [9] SYSCTL_PPGPIO_P9 — GPIO Port K Present
  [8] SYSCTL_PPGPIO_P8 — GPIO Port J Present
  [7] SYSCTL_PPGPIO_P7 — GPIO Port H Present
  [6] SYSCTL_PPGPIO_P6 — GPIO Port G Present
  [5] SYSCTL_PPGPIO_P5 — GPIO Port F Present
  [4] SYSCTL_PPGPIO_P4 — GPIO Port E Present
  [3] SYSCTL_PPGPIO_P3 — GPIO Port D Present
  [2] SYSCTL_PPGPIO_P2 — GPIO Port C Present
  [1] SYSCTL_PPGPIO_P1 — GPIO Port B Present
  [0] SYSCTL_PPGPIO_P0 — GPIO Port A Present
0x30C PPDMA — Micro Direct Memory Access Peripheral Present
  [0] SYSCTL_PPDMA_P0 — uDMA Module Present
0x310 PPEPI — External Peripheral Interface Peripheral Present
  [0] SYSCTL_PPEPI_P0 — EPI Module Present
0x314 PPHIB — Hibernation Peripheral Present
  [0] SYSCTL_PPHIB_P0 — Hibernation Module Present
0x318 PPUART — Universal Asynchronous Receiver/Transmitter Peripheral Present
  [n] SYSCTL_PPUART_P{n} (n=0..7) — UART Module {n} Present
0x31C PPSSI — Synchronous Serial Interface Peripheral Present
  [n] SYSCTL_PPSSI_P{n} (n=0..3) — SSI Module {n} Present
0x320 PPI2C — Inter-Integrated Circuit Peripheral Present
  [n] SYSCTL_PPI2C_P{n} (n=0..5) — I2C Module {n} Present
0x324 PPI2S — Inter-Integrated Circuit Sound Peripheral Present
  [0] SYSCTL_PPI2S_P0 — I2S Module Present
0x328 PPUSB — Universal Serial Bus Peripheral Present
  [0] SYSCTL_PPUSB_P0 — USB Module Present
0x32C PPETH — Ethernet MAC Peripheral Present
  [0] SYSCTL_PPETH_P0 — Ethernet MAC Module Present
0x330 PPETHPHY — Ethernet PHY Peripheral Present
  [0] SYSCTL_PPETHPHY_P0 — Ethernet PHY Module Present
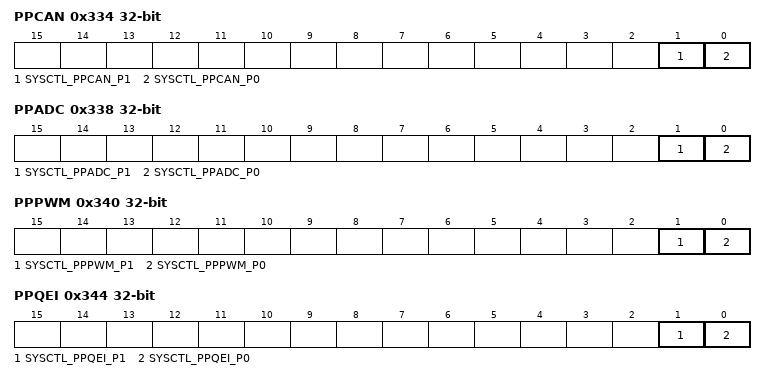
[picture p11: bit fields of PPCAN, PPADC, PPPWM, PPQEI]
0x334 PPCAN — Controller Area Network Peripheral Present
  [1] SYSCTL_PPCAN_P1 — CAN Module 1 Present
  [0] SYSCTL_PPCAN_P0 — CAN Module 0 Present
0x338 PPADC — Analog-to-Digital Converter Peripheral Present
  [1] SYSCTL_PPADC_P1 — ADC Module 1 Present
  [0] SYSCTL_PPADC_P0 — ADC Module 0 Present
0x33C PPACMP — Analog Comparator Peripheral Present
  [0] SYSCTL_PPACMP_P0 — Analog Comparator Module Present
0x340 PPPWM — Pulse Width Modulator Peripheral Present
  [1] SYSCTL_PPPWM_P1 — PWM Module 1 Present
  [0] SYSCTL_PPPWM_P0 — PWM Module 0 Present
0x344 PPQEI — Quadrature Encoder Interface Peripheral Present
  [1] SYSCTL_PPQEI_P1 — QEI Module 1 Present
  [0] SYSCTL_PPQEI_P0 — QEI Module 0 Present
0x358 PPEEPROM — EEPROM Peripheral Present
  [0] SYSCTL_PPEEPROM_P0 — EEPROM Module Present
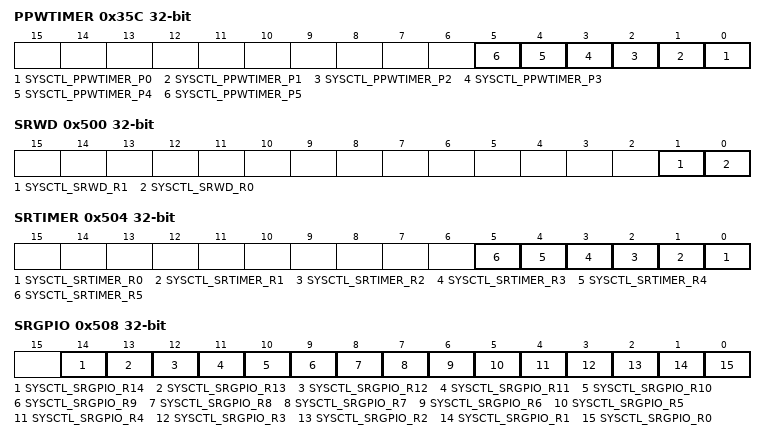
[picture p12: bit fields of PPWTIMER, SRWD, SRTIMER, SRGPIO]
0x35C PPWTIMER — Wide Timer Peripheral Present
  [n] SYSCTL_PPWTIMER_P{n} (n=0..5) — Wide Timer {n} Present
0x500 SRWD — Watchdog Timer Software Reset
  [1] SYSCTL_SRWD_R1 — Watchdog Timer 1 Software Reset
  [0] SYSCTL_SRWD_R0 — Watchdog Timer 0 Software Reset
0x504 SRTIMER — Timer Software Reset
  [n] SYSCTL_SRTIMER_R{n} (n=0..5) — Timer {n} Software Reset
0x508 SRGPIO — General-Purpose Input/Output Software Reset
  [14] SYSCTL_SRGPIO_R14 — GPIO Port Q Software Reset
  [13] SYSCTL_SRGPIO_R13 — GPIO Port P Software Reset
  [12] SYSCTL_SRGPIO_R12 — GPIO Port N Software Reset
  [11] SYSCTL_SRGPIO_R11 — GPIO Port M Software Reset
  [10] SYSCTL_SRGPIO_R10 — GPIO Port L Software Reset
  [9] SYSCTL_SRGPIO_R9 — GPIO Port K Software Reset
  [8] SYSCTL_SRGPIO_R8 — GPIO Port J Software Reset
  [7] SYSCTL_SRGPIO_R7 — GPIO Port H Software Reset
  [6] SYSCTL_SRGPIO_R6 — GPIO Port G Software Reset
  [5] SYSCTL_SRGPIO_R5 — GPIO Port F Software Reset
  [4] SYSCTL_SRGPIO_R4 — GPIO Port E Software Reset
  [3] SYSCTL_SRGPIO_R3 — GPIO Port D Software Reset
  [2] SYSCTL_SRGPIO_R2 — GPIO Port C Software Reset
  [1] SYSCTL_SRGPIO_R1 — GPIO Port B Software Reset
  [0] SYSCTL_SRGPIO_R0 — GPIO Port A Software Reset
0x50C SRDMA — Micro Direct Memory Access Software Reset
  [0] SYSCTL_SRDMA_R0 — uDMA Module Software Reset
0x514 SRHIB — Hibernation Software Reset
  [0] SYSCTL_SRHIB_R0 — Hibernation Module Software Reset
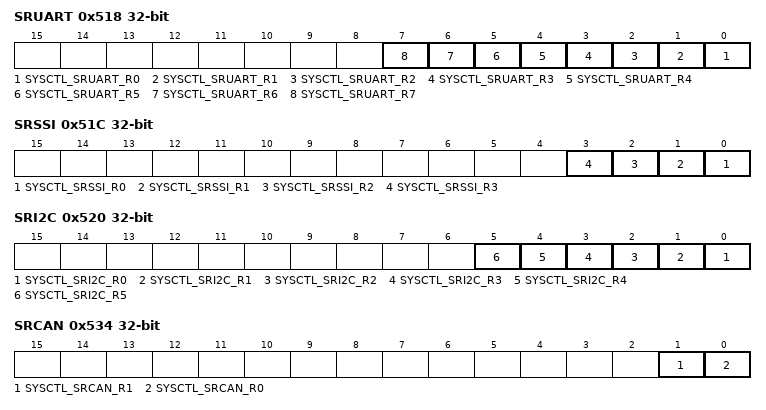
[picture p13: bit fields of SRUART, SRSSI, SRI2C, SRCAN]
0x518 SRUART — Universal Asynchronous Receiver/Transmitter Software Reset
  [n] SYSCTL_SRUART_R{n} (n=0..7) — UART Module {n} Software Reset
0x51C SRSSI — Synchronous Serial Interface Software Reset
  [n] SYSCTL_SRSSI_R{n} (n=0..3) — SSI Module {n} Software Reset
0x520 SRI2C — Inter-Integrated Circuit Software Reset
  [n] SYSCTL_SRI2C_R{n} (n=0..5) — I2C Module {n} Software Reset
0x528 SRUSB — Universal Serial Bus Software Reset
  [0] SYSCTL_SRUSB_R0 — USB Module Software Reset
0x534 SRCAN — Controller Area Network Software Reset
  [1] SYSCTL_SRCAN_R1 — CAN Module 1 Software Reset
  [0] SYSCTL_SRCAN_R0 — CAN Module 0 Software Reset
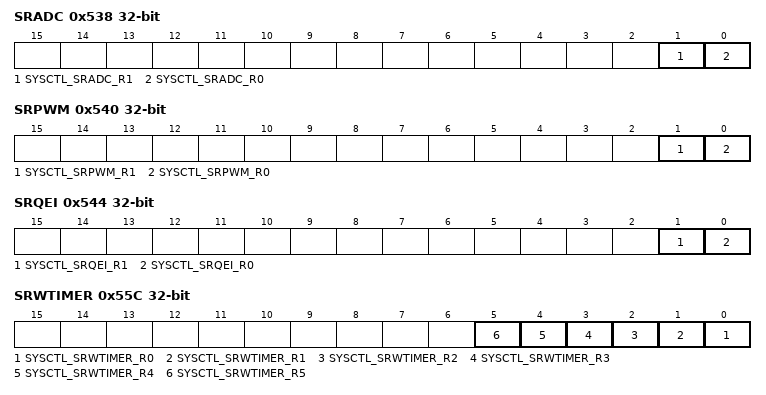
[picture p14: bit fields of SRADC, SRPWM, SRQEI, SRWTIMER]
0x538 SRADC — Analog-to-Digital Converter Software Reset
  [1] SYSCTL_SRADC_R1 — ADC Module 1 Software Reset
  [0] SYSCTL_SRADC_R0 — ADC Module 0 Software Reset
0x53C SRACMP — Analog Comparator Software Reset
  [0] SYSCTL_SRACMP_R0 — Analog Comparator Module Software Reset
0x540 SRPWM — Pulse Width Modulator Software Reset
  [1] SYSCTL_SRPWM_R1 — PWM Module 1 Software Reset
  [0] SYSCTL_SRPWM_R0 — PWM Module 0 Software Reset
0x544 SRQEI — Quadrature Encoder Interface Software Reset
  [1] SYSCTL_SRQEI_R1 — QEI Module 1 Software Reset
  [0] SYSCTL_SRQEI_R0 — QEI Module 0 Software Reset
0x558 SREEPROM — EEPROM Software Reset
  [0] SYSCTL_SREEPROM_R0 — EEPROM Module Software Reset
0x55C SRWTIMER — Wide Timer Software Reset
  [n] SYSCTL_SRWTIMER_R{n} (n=0..5) — Wide Timer {n} Software Reset
0x600 RCGCWD — Watchdog Timer Run Mode Clock Gating Control
  [1] SYSCTL_RCGCWD_R1 — Watchdog Timer 1 Run Mode Clock Gating Control
  [0] SYSCTL_RCGCWD_R0 — Watchdog Timer 0 Run Mode Clock Gating Control
0x604 RCGCTIMER — Timer Run Mode Clock Gating Control
  [n] SYSCTL_RCGCTIMER_R{n} (n=0..5) — Timer {n} Run Mode Clock Gating Control
0x608 RCGCGPIO — General-Purpose Input/Output Run Mode Clock Gating Control
  [14] SYSCTL_RCGCGPIO_R14 — GPIO Port Q Run Mode Clock Gating Control
  [13] SYSCTL_RCGCGPIO_R13 — GPIO Port P Run Mode Clock Gating Control
  [12] SYSCTL_RCGCGPIO_R12 — GPIO Port N Run Mode Clock Gating Control
  [11] SYSCTL_RCGCGPIO_R11 — GPIO Port M Run Mode Clock Gating Control
  [10] SYSCTL_RCGCGPIO_R10 — GPIO Port L Run Mode Clock Gating Control
  [9] SYSCTL_RCGCGPIO_R9 — GPIO Port K Run Mode Clock Gating Control
  [8] SYSCTL_RCGCGPIO_R8 — GPIO Port J Run Mode Clock Gating Control
  [7] SYSCTL_RCGCGPIO_R7 — GPIO Port H Run Mode Clock Gating Control
  [6] SYSCTL_RCGCGPIO_R6 — GPIO Port G Run Mode Clock Gating Control
  [5] SYSCTL_RCGCGPIO_R5 — GPIO Port F Run Mode Clock Gating Control
  [4] SYSCTL_RCGCGPIO_R4 — GPIO Port E Run Mode Clock Gating Control
  [3] SYSCTL_RCGCGPIO_R3 — GPIO Port D Run Mode Clock Gating Control
  [2] SYSCTL_RCGCGPIO_R2 — GPIO Port C Run Mode Clock Gating Control
  [1] SYSCTL_RCGCGPIO_R1 — GPIO Port B Run Mode Clock Gating Control
  [0] SYSCTL_RCGCGPIO_R0 — GPIO Port A Run Mode Clock Gating Control
0x60C RCGCDMA — Micro Direct Memory Access Run Mode Clock Gating Control
  [0] SYSCTL_RCGCDMA_R0 — uDMA Module Run Mode Clock Gating Control
0x614 RCGCHIB — Hibernation Run Mode Clock Gating Control
  [0] SYSCTL_RCGCHIB_R0 — Hibernation Module Run Mode Clock Gating Control
0x618 RCGCUART — Universal Asynchronous Receiver/Transmitter Run Mode Clock Gating Control
  [n] SYSCTL_RCGCUART_R{n} (n=0..7) — UART Module {n} Run Mode Clock Gating Control
0x61C RCGCSSI — Synchronous Serial Interface Run Mode Clock Gating Control
  [n] SYSCTL_RCGCSSI_R{n} (n=0..3) — SSI Module {n} Run Mode Clock Gating Control
0x620 RCGCI2C — Inter-Integrated Circuit Run Mode Clock Gating Control
  [n] SYSCTL_RCGCI2C_R{n} (n=0..5) — I2C Module {n} Run Mode Clock Gating Control
0x628 RCGCUSB — Universal Serial Bus Run Mode Clock Gating Control
  [0] SYSCTL_RCGCUSB_R0 — USB Module Run Mode Clock Gating Control
0x634 RCGCCAN — Controller Area Network Run Mode Clock Gating Control
  [1] SYSCTL_RCGCCAN_R1 — CAN Module 1 Run Mode Clock Gating Control
  [0] SYSCTL_RCGCCAN_R0 — CAN Module 0 Run Mode Clock Gating Control
0x638 RCGCADC — Analog-to-Digital Converter Run Mode Clock Gating Control
  [1] SYSCTL_RCGCADC_R1 — ADC Module 1 Run Mode Clock Gating Control
  [0] SYSCTL_RCGCADC_R0 — ADC Module 0 Run Mode Clock Gating Control
0x63C RCGCACMP — Analog Comparator Run Mode Clock Gating Control
  [0] SYSCTL_RCGCACMP_R0 — Analog Comparator Module Run Mode Clock Gating Control
0x640 RCGCPWM — Pulse Width Modulator Run Mode Clock Gating Control
  [1] SYSCTL_RCGCPWM_R1 — PWM Module 1 Run Mode Clock Gating Control
  [0] SYSCTL_RCGCPWM_R0 — PWM Module 0 Run Mode Clock Gating Control
0x644 RCGCQEI — Quadrature Encoder Interface Run Mode Clock Gating Control
  [1] SYSCTL_RCGCQEI_R1 — QEI Module 1 Run Mode Clock Gating Control
  [0] SYSCTL_RCGCQEI_R0 — QEI Module 0 Run Mode Clock Gating Control
0x658 RCGCEEPROM — EEPROM Run Mode Clock Gating Control
  [0] SYSCTL_RCGCEEPROM_R0 — EEPROM Module Run Mode Clock Gating Control
0x65C RCGCWTIMER — Wide Timer Run Mode Clock Gating Control
  [n] SYSCTL_RCGCWTIMER_R{n} (n=0..5) — Wide Timer {n} Run Mode Clock Gating Control
0x700 SCGCWD — Watchdog Timer Sleep Mode Clock Gating Control
  [1] SYSCTL_SCGCWD_S1 — Watchdog Timer 1 Sleep Mode Clock Gating Control
  [0] SYSCTL_SCGCWD_S0 — Watchdog Timer 0 Sleep Mode Clock Gating Control
0x704 SCGCTIMER — Timer Sleep Mode Clock Gating Control
  [n] SYSCTL_SCGCTIMER_S{n} (n=0..5) — Timer {n} Sleep Mode Clock Gating Control
0x708 SCGCGPIO — General-Purpose Input/Output Sleep Mode Clock Gating Control
  [14] SYSCTL_SCGCGPIO_S14 — GPIO Port Q Sleep Mode Clock Gating Control
  [13] SYSCTL_SCGCGPIO_S13 — GPIO Port P Sleep Mode Clock Gating Control
  [12] SYSCTL_SCGCGPIO_S12 — GPIO Port N Sleep Mode Clock Gating Control
  [11] SYSCTL_SCGCGPIO_S11 — GPIO Port M Sleep Mode Clock Gating Control
  [10] SYSCTL_SCGCGPIO_S10 — GPIO Port L Sleep Mode Clock Gating Control
  [9] SYSCTL_SCGCGPIO_S9 — GPIO Port K Sleep Mode Clock Gating Control
  [8] SYSCTL_SCGCGPIO_S8 — GPIO Port J Sleep Mode Clock Gating Control
  [7] SYSCTL_SCGCGPIO_S7 — GPIO Port H Sleep Mode Clock Gating Control
  [6] SYSCTL_SCGCGPIO_S6 — GPIO Port G Sleep Mode Clock Gating Control
  [5] SYSCTL_SCGCGPIO_S5 — GPIO Port F Sleep Mode Clock Gating Control
  [4] SYSCTL_SCGCGPIO_S4 — GPIO Port E Sleep Mode Clock Gating Control
  [3] SYSCTL_SCGCGPIO_S3 — GPIO Port D Sleep Mode Clock Gating Control
  [2] SYSCTL_SCGCGPIO_S2 — GPIO Port C Sleep Mode Clock Gating Control
  [1] SYSCTL_SCGCGPIO_S1 — GPIO Port B Sleep Mode Clock Gating Control
  [0] SYSCTL_SCGCGPIO_S0 — GPIO Port A Sleep Mode Clock Gating Control
0x70C SCGCDMA — Micro Direct Memory Access Sleep Mode Clock Gating Control
  [0] SYSCTL_SCGCDMA_S0 — uDMA Module Sleep Mode Clock Gating Control
0x714 SCGCHIB — Hibernation Sleep Mode Clock Gating Control
  [0] SYSCTL_SCGCHIB_S0 — Hibernation Module Sleep Mode Clock Gating Control
0x718 SCGCUART — Universal Asynchronous Receiver/Transmitter Sleep Mode Clock Gating Control
  [n] SYSCTL_SCGCUART_S{n} (n=0..7) — UART Module {n} Sleep Mode Clock Gating Control
0x71C SCGCSSI — Synchronous Serial Interface Sleep Mode Clock Gating Control
  [n] SYSCTL_SCGCSSI_S{n} (n=0..3) — SSI Module {n} Sleep Mode Clock Gating Control
0x720 SCGCI2C — Inter-Integrated Circuit Sleep Mode Clock Gating Control
  [n] SYSCTL_SCGCI2C_S{n} (n=0..5) — I2C Module {n} Sleep Mode Clock Gating Control
0x728 SCGCUSB — Universal Serial Bus Sleep Mode Clock Gating Control
  [0] SYSCTL_SCGCUSB_S0 — USB Module Sleep Mode Clock Gating Control
0x734 SCGCCAN — Controller Area Network Sleep Mode Clock Gating Control
  [1] SYSCTL_SCGCCAN_S1 — CAN Module 1 Sleep Mode Clock Gating Control
  [0] SYSCTL_SCGCCAN_S0 — CAN Module 0 Sleep Mode Clock Gating Control
0x738 SCGCADC — Analog-to-Digital Converter Sleep Mode Clock Gating Control
  [1] SYSCTL_SCGCADC_S1 — ADC Module 1 Sleep Mode Clock Gating Control
  [0] SYSCTL_SCGCADC_S0 — ADC Module 0 Sleep Mode Clock Gating Control
0x73C SCGCACMP — Analog Comparator Sleep Mode Clock Gating Control
  [0] SYSCTL_SCGCACMP_S0 — Analog Comparator Module Sleep Mode Clock Gating Control
0x740 SCGCPWM — Pulse Width Modulator Sleep Mode Clock Gating Control
  [1] SYSCTL_SCGCPWM_S1 — PWM Module 1 Sleep Mode Clock Gating Control
  [0] SYSCTL_SCGCPWM_S0 — PWM Module 0 Sleep Mode Clock Gating Control
0x744 SCGCQEI — Quadrature Encoder Interface Sleep Mode Clock Gating Control
  [1] SYSCTL_SCGCQEI_S1 — QEI Module 1 Sleep Mode Clock Gating Control
  [0] SYSCTL_SCGCQEI_S0 — QEI Module 0 Sleep Mode Clock Gating Control
0x758 SCGCEEPROM — EEPROM Sleep Mode Clock Gating Control
  [0] SYSCTL_SCGCEEPROM_S0 — EEPROM Module Sleep Mode Clock Gating Control
0x75C SCGCWTIMER — Wide Timer Sleep Mode Clock Gating Control
  [n] SYSCTL_SCGCWTIMER_S{n} (n=0..5) — Wide Timer {n} Sleep Mode Clock Gating Control
0x800 DCGCWD — Watchdog Timer Deep-Sleep Mode Clock Gating Control
  [1] SYSCTL_DCGCWD_D1 — Watchdog Timer 1 Deep-Sleep Mode Clock Gating Control
  [0] SYSCTL_DCGCWD_D0 — Watchdog Timer 0 Deep-Sleep Mode Clock Gating Control
0x804 DCGCTIMER — Timer Deep-Sleep Mode Clock Gating Control
  [n] SYSCTL_DCGCTIMER_D{n} (n=0..5) — Timer {n} Deep-Sleep Mode Clock Gating Control
0x808 DCGCGPIO — General-Purpose Input/Output Deep-Sleep Mode Clock Gating Control
  [14] SYSCTL_DCGCGPIO_D14 — GPIO Port Q Deep-Sleep Mode Clock Gating Control
  [13] SYSCTL_DCGCGPIO_D13 — GPIO Port P Deep-Sleep Mode Clock Gating Control
  [12] SYSCTL_DCGCGPIO_D12 — GPIO Port N Deep-Sleep Mode Clock Gating Control
  [11] SYSCTL_DCGCGPIO_D11 — GPIO Port M Deep-Sleep Mode Clock Gating Control
  [10] SYSCTL_DCGCGPIO_D10 — GPIO Port L Deep-Sleep Mode Clock Gating Control
  [9] SYSCTL_DCGCGPIO_D9 — GPIO Port K Deep-Sleep Mode Clock Gating Control
  [8] SYSCTL_DCGCGPIO_D8 — GPIO Port J Deep-Sleep Mode Clock Gating Control
  [7] SYSCTL_DCGCGPIO_D7 — 0Mode Clock Gating Control
  [6] SYSCTL_DCGCGPIO_D6 — GPIO Port G Deep-Sleep Mode Clock Gating Control
  [5] SYSCTL_DCGCGPIO_D5 — GPIO Port F Deep-Sleep Mode Clock Gating Control
  [4] SYSCTL_DCGCGPIO_D4 — GPIO Port E Deep-Sleep Mode Clock Gating Control
  [3] SYSCTL_DCGCGPIO_D3 — GPIO Port D Deep-Sleep Mode Clock Gating Control
  [2] SYSCTL_DCGCGPIO_D2 — GPIO Port C Deep-Sleep Mode Clock Gating Control
  [1] SYSCTL_DCGCGPIO_D1 — GPIO Port B Deep-Sleep Mode Clock Gating Control
  [0] SYSCTL_DCGCGPIO_D0 — GPIO Port A Deep-Sleep Mode Clock Gating Control
0x80C DCGCDMA — Micro Direct Memory Access Deep-Sleep Mode Clock Gating Control
  [0] SYSCTL_DCGCDMA_D0 — uDMA Module Deep-Sleep Mode Clock Gating Control
0x814 DCGCHIB — Hibernation Deep-Sleep Mode Clock Gating Control
  [0] SYSCTL_DCGCHIB_D0 — Hibernation Module Deep-Sleep Mode Clock Gating Control
0x818 DCGCUART — Universal Asynchronous Receiver/Transmitter Deep-Sleep Mode Clock Gating Control
  [n] SYSCTL_DCGCUART_D{n} (n=0..7) — UART Module {n} Deep-Sleep Mode Clock Gating Control
0x81C DCGCSSI — Synchronous Serial Interface Deep-Sleep Mode Clock Gating Control
  [n] SYSCTL_DCGCSSI_D{n} (n=0..3) — SSI Module {n} Deep-Sleep Mode Clock Gating Control
0x820 DCGCI2C — Inter-Integrated Circuit Deep-Sleep Mode Clock Gating Control
  [n] SYSCTL_DCGCI2C_D{n} (n=0..5) — I2C Module {n} Deep-Sleep Mode Clock Gating Control
0x828 DCGCUSB — Universal Serial Bus Deep-Sleep Mode Clock Gating Control
  [0] SYSCTL_DCGCUSB_D0 — USB Module Deep-Sleep Mode Clock Gating Control
0x834 DCGCCAN — Controller Area Network Deep-Sleep Mode Clock Gating Control
  [1] SYSCTL_DCGCCAN_D1 — CAN Module 1 Deep-Sleep Mode Clock Gating Control
  [0] SYSCTL_DCGCCAN_D0 — CAN Module 0 Deep-Sleep Mode Clock Gating Control
0x838 DCGCADC — Analog-to-Digital Converter Deep-Sleep Mode Clock Gating Control
  [1] SYSCTL_DCGCADC_D1 — ADC Module 1 Deep-Sleep Mode Clock Gating Control
  [0] SYSCTL_DCGCADC_D0 — ADC Module 0 Deep-Sleep Mode Clock Gating Control
0x83C DCGCACMP — Analog Comparator Deep-Sleep Mode Clock Gating Control
  [0] SYSCTL_DCGCACMP_D0 — Analog Comparator Module Deep-Sleep Mode Clock Gating Control
0x840 DCGCPWM — Pulse Width Modulator Deep-Sleep Mode Clock Gating Control
  [1] SYSCTL_DCGCPWM_D1 — PWM Module 1 Deep-Sleep Mode Clock Gating Control
  [0] SYSCTL_DCGCPWM_D0 — PWM Module 0 Deep-Sleep Mode Clock Gating Control
0x844 DCGCQEI — Quadrature Encoder Interface Deep-Sleep Mode Clock Gating Control
  [1] SYSCTL_DCGCQEI_D1 — QEI Module 1 Deep-Sleep Mode Clock Gating Control
  [0] SYSCTL_DCGCQEI_D0 — QEI Module 0 Deep-Sleep Mode Clock Gating Control
0x858 DCGCEEPROM — EEPROM Deep-Sleep Mode Clock Gating Control
  [0] SYSCTL_DCGCEEPROM_D0 — EEPROM Module Deep-Sleep Mode Clock Gating Control
0x85C DCGCWTIMER — Wide Timer Deep-Sleep Mode Clock Gating Control
  [n] SYSCTL_DCGCWTIMER_D{n} (n=0..5) — Wide Timer {n} Deep-Sleep Mode Clock Gating Control
0x900 PCWD — Watchdog Timer Power Control
  [1] SYSCTL_PCWD_P1 — Watchdog Timer 1 Power Control
  [0] SYSCTL_PCWD_P0 — Watchdog Timer 0 Power Control
0x904 PCTIMER — Timer Power Control
  [n] SYSCTL_PCTIMER_P{n} (n=0..5) — Timer {n} Power Control
0x908 PCGPIO — General-Purpose Input/Output Power Control
  [14] SYSCTL_PCGPIO_P14 — GPIO Port Q Power Control
  [13] SYSCTL_PCGPIO_P13 — GPIO Port P Power Control
  [12] SYSCTL_PCGPIO_P12 — GPIO Port N Power Control
  [11] SYSCTL_PCGPIO_P11 — GPIO Port M Power Control
  [10] SYSCTL_PCGPIO_P10 — GPIO Port L Power Control
  [9] SYSCTL_PCGPIO_P9 — GPIO Port K Power Control
  [8] SYSCTL_PCGPIO_P8 — GPIO Port J Power Control
  [7] SYSCTL_PCGPIO_P7 — GPIO Port H Power Control
  [6] SYSCTL_PCGPIO_P6 — GPIO Port G Power Control
  [5] SYSCTL_PCGPIO_P5 — GPIO Port F Power Control
  [4] SYSCTL_PCGPIO_P4 — GPIO Port E Power Control
  [3] SYSCTL_PCGPIO_P3 — GPIO Port D Power Control
  [2] SYSCTL_PCGPIO_P2 — GPIO Port C Power Control
  [1] SYSCTL_PCGPIO_P1 — GPIO Port B Power Control
  [0] SYSCTL_PCGPIO_P0 — GPIO Port A Power Control
0x90C PCDMA — Micro Direct Memory Access Power Control
  [0] SYSCTL_PCDMA_P0 — uDMA Module Power Control
0x914 PCHIB — Hibernation Power Control
  [0] SYSCTL_PCHIB_P0 — Hibernation Module Power Control
0x918 PCUART — Universal Asynchronous Receiver/Transmitter Power Control
  [n] SYSCTL_PCUART_P{n} (n=0..7) — UART Module {n} Power Control
0x91C PCSSI — Synchronous Serial Interface Power Control
  [n] SYSCTL_PCSSI_P{n} (n=0..3) — SSI Module {n} Power Control
0x920 PCI2C — Inter-Integrated Circuit Power Control
  [n] SYSCTL_PCI2C_P{n} (n=0..5) — I2C Module {n} Power Control
0x928 PCUSB — Universal Serial Bus Power Control
  [0] SYSCTL_PCUSB_P0 — USB Module Power Control
0x934 PCCAN — Controller Area Network Power Control
  [1] SYSCTL_PCCAN_P1 — CAN Module 1 Power Control
  [0] SYSCTL_PCCAN_P0 — CAN Module 0 Power Control
0x938 PCADC — Analog-to-Digital Converter Power Control
  [1] SYSCTL_PCADC_P1 — ADC Module 1 Power Control
  [0] SYSCTL_PCADC_P0 — ADC Module 0 Power Control
0x93C PCACMP — Analog Comparator Power Control
  [0] SYSCTL_PCACMP_P0 — Analog Comparator Module 0 Power Control
0x940 PCPWM — Pulse Width Modulator Power Control
  [1] SYSCTL_PCPWM_P1 — PWM Module 1 Power Control
  [0] SYSCTL_PCPWM_P0 — PWM Module 0 Power Control
0x944 PCQEI — Quadrature Encoder Interface Power Control
  [1] SYSCTL_PCQEI_P1 — QEI Module 1 Power Control
  [0] SYSCTL_PCQEI_P0 — QEI Module 0 Power Control
0x958 PCEEPROM — EEPROM Power Control
  [0] SYSCTL_PCEEPROM_P0 — EEPROM Module Power Control
0x95C PCWTIMER — Wide Timer Power Control
  [n] SYSCTL_PCWTIMER_P{n} (n=0..5) — Wide Timer {n} Power Control
0xA00 PRWD — Watchdog Timer Peripheral Ready
  [1] SYSCTL_PRWD_R1 — Watchdog Timer 1 Peripheral Ready
  [0] SYSCTL_PRWD_R0 — Watchdog Timer 0 Peripheral Ready
0xA04 PRTIMER — Timer Peripheral Ready
  [n] SYSCTL_PRTIMER_R{n} (n=0..5) — Timer {n} Peripheral Ready
0xA08 PRGPIO — General-Purpose Input/Output Peripheral Ready
  [14] SYSCTL_PRGPIO_R14 — GPIO Port Q Peripheral Ready
  [13] SYSCTL_PRGPIO_R13 — GPIO Port P Peripheral Ready
  [12] SYSCTL_PRGPIO_R12 — GPIO Port N Peripheral Ready
  [11] SYSCTL_PRGPIO_R11 — GPIO Port M Peripheral Ready
  [10] SYSCTL_PRGPIO_R10 — GPIO Port L Peripheral Ready
  [9] SYSCTL_PRGPIO_R9 — GPIO Port K Peripheral Ready
  [8] SYSCTL_PRGPIO_R8 — GPIO Port J Peripheral Ready
  [7] SYSCTL_PRGPIO_R7 — GPIO Port H Peripheral Ready
  [6] SYSCTL_PRGPIO_R6 — GPIO Port G Peripheral Ready
  [5] SYSCTL_PRGPIO_R5 — GPIO Port F Peripheral Ready
  [4] SYSCTL_PRGPIO_R4 — GPIO Port E Peripheral Ready
  [3] SYSCTL_PRGPIO_R3 — GPIO Port D Peripheral Ready
  [2] SYSCTL_PRGPIO_R2 — GPIO Port C Peripheral Ready
  [1] SYSCTL_PRGPIO_R1 — GPIO Port B Peripheral Ready
  [0] SYSCTL_PRGPIO_R0 — GPIO Port A Peripheral Ready
0xA0C PRDMA — Micro Direct Memory Access Peripheral Ready
  [0] SYSCTL_PRDMA_R0 — uDMA Module Peripheral Ready
0xA14 PRHIB — Hibernation Peripheral Ready
  [0] SYSCTL_PRHIB_R0 — Hibernation Module Peripheral Ready
0xA18 PRUART — Universal Asynchronous Receiver/Transmitter Peripheral Ready
  [n] SYSCTL_PRUART_R{n} (n=0..7) — UART Module {n} Peripheral Ready
0xA1C PRSSI — Synchronous Serial Interface Peripheral Ready
  [n] SYSCTL_PRSSI_R{n} (n=0..3) — SSI Module {n} Peripheral Ready
0xA20 PRI2C — Inter-Integrated Circuit Peripheral Ready
  [n] SYSCTL_PRI2C_R{n} (n=0..5) — I2C Module {n} Peripheral Ready
0xA28 PRUSB — Universal Serial Bus Peripheral Ready
  [0] SYSCTL_PRUSB_R0 — USB Module Peripheral Ready
0xA34 PRCAN — Controller Area Network Peripheral Ready
  [1] SYSCTL_PRCAN_R1 — CAN Module 1 Peripheral Ready
  [0] SYSCTL_PRCAN_R0 — CAN Module 0 Peripheral Ready
0xA38 PRADC — Analog-to-Digital Converter Peripheral Ready
  [1] SYSCTL_PRADC_R1 — ADC Module 1 Peripheral Ready
  [0] SYSCTL_PRADC_R0 — ADC Module 0 Peripheral Ready
0xA3C PRACMP — Analog Comparator Peripheral Ready
  [0] SYSCTL_PRACMP_R0 — Analog Comparator Module Peripheral Ready
0xA40 PRPWM — Pulse Width Modulator Peripheral Ready
  [1] SYSCTL_PRPWM_R1 — PWM Module 1 Peripheral Ready
  [0] SYSCTL_PRPWM_R0 — PWM Module 0 Peripheral Ready
0xA44 PRQEI — Quadrature Encoder Interface Peripheral Ready
  [1] SYSCTL_PRQEI_R1 — QEI Module 1 Peripheral Ready
  [0] SYSCTL_PRQEI_R0 — QEI Module 0 Peripheral Ready
0xA58 PREEPROM — EEPROM Peripheral Ready
  [0] SYSCTL_PREEPROM_R0 — EEPROM Module Peripheral Ready
0xA5C PRWTIMER — Wide Timer Peripheral Ready
  [n] SYSCTL_PRWTIMER_R{n} (n=0..5) — Wide Timer {n} Peripheral Ready
